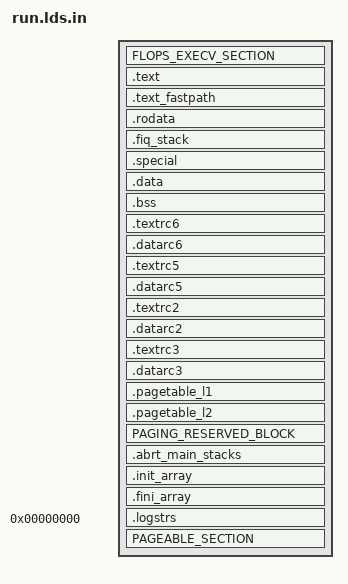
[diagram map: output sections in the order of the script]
OUTPUT_ARCH(TARGET_ARCH)
ENTRY(startup)
SECTIONS {

	FLOPS_EXECV_SECTION

	. = TEXT_START;

	/* Start of MPU protection region. Generate exceptions on writes to text/rodata sections. */
	_ram_mpu_region_start = .;

	.text : {
		_ftext = .;
		text_start = .;
		*(.text.startup)
		*(.text.startup.*)
		KEEP(*(.text.debugptr))
		*(.init)
		FIRMWARE_TEXT_SECTION
		*(.fini)
		*(.glue_7)
		*(.glue_7t)
		. = ALIGN(8);
	}

	. = ALIGN(4);

	.text_fastpath : {
		fastpath_start = .;
		*(.text_fastpath)
		*(.text_fastpath.*)
		fastpath_end = .;
		_etext = .;
		text_end = .;
	}

	. = ALIGN(4096);

	.rodata : {
		rodata_start = .;
		*(.rdata)
		*(.rdata.*)
		FIRMWARE_RODATA_SECTION
		. = ALIGN(4);
		rodata_end = .;
	}

	/* End of MPU protection region. Generate exceptions on writes to text/rodata sections. */
	_ram_mpu_region_end = .;

	. = ALIGN(4096);
	_ram_rw_data_start = .;
	.fiq_stack : {
		*(.data.stack.*)
	}

	/* Place all special input sections here. e.g. code that should not execute post-attach. */
	.special : {
		special_start = .;
		KEEP(*(.special.*))
		special_end = .;
	}

	.data ALIGN(4): {
		_fdata = .;
		data_start = .;
		*(.data)
		*(.data.*)
		*(.sdata)
		. = ALIGN(8);
		_edata = .;
		data_end = .;
	}

	.bss BLOCK(16) : {
		_fbss = .;
		bss_start = .;
		*(.bss)
		*(.bss.*)
		*(.sbss)
		*(.scommon)
		*(COMMON)
		bss_end = .;
	}

	/* Reclaim region 6 for BCMATTACHMLODATA/BCMATTACHMLOFN */
	.textrc6 : {
		. = ALIGN(4);
		_rstart6 = .;
		*(.textini6.*)
	}
	.datarc6 : {
		*(.rodataini6.*)
		*(.dataini6.*)
		. = ALIGN(4);
		_rend6 = .;
	}

	/* Reclaim region 5 for BCMPOSTATTACHDATA/BCMPOSTATTACHFN */
	.textrc5 : {
		. = ALIGN(4);
		_rstart5 = .;
		*(.textini5.*)
	}
	.datarc5 : {
		*(.rodataini5.*)
		*(.dataini5.*)
		. = ALIGN(4);
		_rend5 = .;
	}

	/* Reclaim region 2 for BCMATTACHFN/BCMATTACHDATA */
	.textrc2 : {
		_rstart2 = .;
		*(.textini2.*)
	}
	.datarc2 : {
		. = ALIGN(4);
		*(.rodataini2*)
		*(.dataini2.*)

		/* Align _rend2 so that it is contiguous with the next section. This allows the
		 * 2 sections to be joined into a single free heap block after both sections have
		 * been reclaimed. This helps avoid fragmentation.
		 */
		. = ALIGN(4);
		_rend2 = .;
	}

	/* Reclaim region 3 for BCMPREATTACHDATA/BCMPREATTACHFN */
	.textrc3 : {
		_rstart3 = .;
		*(.textini3.*)
	}
	.datarc3 : {
		*(.rodataini3.*)
		*(.dataini3.*)
	}

	.pagetable_l1 : {
		/* Note: the following alignment is to get the pagetables starting aligned on
		 * 16K. The L1 page table requires this. Do not place any other sections between
		 * this alignment and the l1 pagetable. The _rend3 marker is put here to get the
		 * end of data section (becomes HEAP).
		 */
		. = ALIGN(16384);
		_rend3 = .;
		pagetable_start = .;
		*(.pagetable1.*)
	}

	/* Have the L1 pagetable followed by L2 pagetable !. Do not put any other section in
	 * between. Two situations are possible. If SWPaging is supported then the L2 table needs
	 * to be write-able. If not then it can be marked as RO. This is done by marking two
	 * places where the pagetable2 area can be put. Before or after the pagetable_end label.
	 * The ALIGN markers are for: L2 pagetable needs to start aligned at 1024 boundary, and
	 * size of the RO pagetable section needs to be multiple of 4096 so it can be marked RO
	 * in the page table.
	 */
	.pagetable_l2 : {
		. = ALIGN(1024);
		PAGETABLE2_RO
		. = ALIGN(4096);
		pagetable_end = .;
		PAGETABLE2_RW
	}

	PAGING_RESERVED_BLOCK

	.abrt_main_stacks : {
		. = ALIGN(4096);
		*(.sdata.stack1.*)
		*(.sdata.stack2.*)
	}

	.init_array : {
		__init_array_start = .;
		KEEP(*(.init_array))
		KEEP(*(SORT_BY_INIT_PRIORITY(.init_array.*)))
		__init_array_end = .;
	}

	.fini_array : {
		__fini_array_start = .;
		KEEP(*(.fini_array))
		KEEP(*(SORT_BY_INIT_PRIORITY(.fini_array.*)))
		__fini_array_end = .;
	}

	_end = .;

	/* Firmware meta-data (CRC, fwtag) is appended to the end of the image. */
	_fw_meta_data = .;

	.logstrs 0 (OVERLAY) : {
		rom_lognums_offset = .;
		KEEP(*(.romlognums))
		ram_lognums_offset = .;
		KEEP(*(.lognums))
		rom_logstrs_offset = .;
		KEEP(*(.romlogstrs))
		ram_logstrs_offset = .;
		KEEP(*(.logstrs))

		/* Header */
		. = ALIGN(4);
		LONG(logstrs_size)		/* Size of this file */
		LONG(rom_lognums_offset)
		LONG(ram_lognums_offset)
		LONG(rom_logstrs_offset)
		LONG(ram_logstrs_offset)
		LONG(1)				/* Header version */
		LONG(0x4C4F4753)	/* MAGIC number for verification 'LOGS' */
		logstrs_size = .;
	}

	PAGEABLE_SECTION
}
